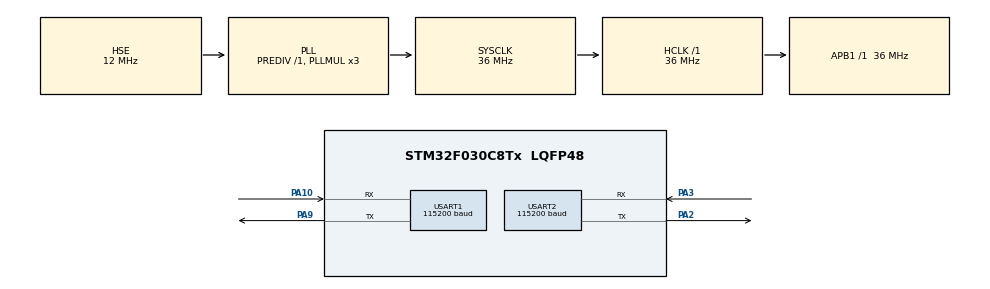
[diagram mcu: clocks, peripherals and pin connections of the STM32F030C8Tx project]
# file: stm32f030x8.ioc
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IWDG.Prescaler=IWDG_PRESCALER_256
Mcu.Family=STM32F0
Mcu.Name=STM32F030C8Tx
Mcu.Package=LQFP48
PA10.Mode=Asynchronous
PA10.Signal=USART1_RX
PA2.Mode=Asynchronous
PA2.Signal=USART2_TX
PA3.Mode=Asynchronous
PA3.Signal=USART2_RX
PA9.Mode=Asynchronous
PA9.Signal=USART1_TX
PF0-OSC_IN.Mode=HSE-External-Oscillator
PF0-OSC_IN.Signal=RCC_OSC_IN
PF1-OSC_OUT.Mode=HSE-External-Oscillator
PF1-OSC_OUT.Signal=RCC_OSC_OUT
ProjectManager.HeapSize=0x200
ProjectManager.StackSize=0x400
ProjectManager.TargetToolchain=Makefile
RCC.AHBFreq_Value=36000000
RCC.APB1Freq_Value=36000000
RCC.APB1TimFreq_Value=36000000
RCC.HCLKFreq_Value=36000000
RCC.HSE_VALUE=12000000
RCC.PLLMUL=RCC_PLL_MUL3
RCC.PLLSourceVirtual=RCC_PLLSOURCE_HSE
RCC.SYSCLKFreq_VALUE=36000000
RCC.SYSCLKSource=RCC_SYSCLKSOURCE_PLLCLK
USART1.BaudRate=115200
USART1.VirtualMode-Asynchronous=VM_ASYNC
USART2.BaudRate=115200
USART2.VirtualMode-Asynchronous=VM_ASYNC
VP_IWDG_VS_IWDG.Mode=IWDG_Activate
board=custom

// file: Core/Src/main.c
/* USER CODE BEGIN Header */
/**
  ******************************************************************************
  * @file           : main.c
  * @brief          : Main program body
  ******************************************************************************
  * @attention
  *
  * <h2><center>&copy; Copyright (c) 2022 STMicroelectronics.
  * All rights reserved.</center></h2>
  *
  * This software component is licensed by ST under BSD 3-Clause license,
  * the "License"; You may not use this file except in compliance with the
  * License. You may obtain a copy of the License at:
  *                        opensource.org/licenses/BSD-3-Clause
  *
  ******************************************************************************
  */
/* USER CODE END Header */
#include "main.h"

/* USER CODE BEGIN Includes */
#include "main_loop.h"

/* USER CODE END Includes */

IWDG_HandleTypeDef hiwdg;

UART_HandleTypeDef huart1;
UART_HandleTypeDef huart2;

void SystemClock_Config(void);
static void MX_GPIO_Init(void);
static void MX_IWDG_Init(void);
static void MX_USART1_UART_Init(void);
static void MX_USART2_UART_Init(void);

int main(void)
{

  /* MCU Configuration--------------------------------------------------------*/

  /* Reset of all peripherals, Initializes the Flash interface and the Systick. */
  HAL_Init();

  /* Configure the system clock */
  SystemClock_Config();

  /* Initialize all configured peripherals */
  MX_GPIO_Init();
  MX_IWDG_Init();
  MX_USART1_UART_Init();
  MX_USART2_UART_Init();
  /* USER CODE BEGIN 2 */

  /*for (int j=0; j<5; ++j)
  {
    volatile int i = 0;
    for(i=0;i<0x80000;++i) {;}
    HAL_GPIO_WritePin(GPIOB, GPIO_PIN_3, GPIO_PIN_RESET);
    for(i=0;i<0x80000;++i) {;}
    HAL_GPIO_WritePin(GPIOB, GPIO_PIN_3, GPIO_PIN_SET);
  }*/

  HAL_UART_Transmit(&huart1, (uint8_t*)"huart1\n", 7, 1000000);
  HAL_UART_Transmit(&huart2, (uint8_t*)"huart2\n", 7, 1000000);

  /* USER CODE END 2 */

  /* Infinite loop */
  /* USER CODE BEGIN WHILE */

  main_loop();

  while (1)
  {
    /* USER CODE END WHILE */

  }
}

void SystemClock_Config(void)
{
  RCC_OscInitTypeDef RCC_OscInitStruct = {0};
  RCC_ClkInitTypeDef RCC_ClkInitStruct = {0};
  RCC_PeriphCLKInitTypeDef PeriphClkInit = {0};

  /** Initializes the RCC Oscillators according to the specified parameters
  * in the RCC_OscInitTypeDef structure.
  */
  RCC_OscInitStruct.OscillatorType = RCC_OSCILLATORTYPE_LSI|RCC_OSCILLATORTYPE_HSE;
  RCC_OscInitStruct.HSEState = RCC_HSE_ON;
  RCC_OscInitStruct.LSIState = RCC_LSI_ON;
  RCC_OscInitStruct.PLL.PLLState = RCC_PLL_ON;
  RCC_OscInitStruct.PLL.PLLSource = RCC_PLLSOURCE_HSE;
  RCC_OscInitStruct.PLL.PLLMUL = RCC_PLL_MUL3;
  RCC_OscInitStruct.PLL.PREDIV = RCC_PREDIV_DIV1;
  if (HAL_RCC_OscConfig(&RCC_OscInitStruct) != HAL_OK)
  {
    Error_Handler();
  }

  /** Initializes the CPU, AHB and APB buses clocks
  */
  RCC_ClkInitStruct.ClockType = RCC_CLOCKTYPE_HCLK|RCC_CLOCKTYPE_SYSCLK
                              |RCC_CLOCKTYPE_PCLK1;
  RCC_ClkInitStruct.SYSCLKSource = RCC_SYSCLKSOURCE_PLLCLK;
  RCC_ClkInitStruct.AHBCLKDivider = RCC_SYSCLK_DIV1;
  RCC_ClkInitStruct.APB1CLKDivider = RCC_HCLK_DIV1;

  if (HAL_RCC_ClockConfig(&RCC_ClkInitStruct, FLASH_LATENCY_1) != HAL_OK)
  {
    Error_Handler();
  }
  PeriphClkInit.PeriphClockSelection = RCC_PERIPHCLK_USART1;
  PeriphClkInit.Usart1ClockSelection = RCC_USART1CLKSOURCE_PCLK1;
  if (HAL_RCCEx_PeriphCLKConfig(&PeriphClkInit) != HAL_OK)
  {
    Error_Handler();
  }
}

static void MX_IWDG_Init(void)
{

  hiwdg.Instance = IWDG;
  hiwdg.Init.Prescaler = IWDG_PRESCALER_256;
  hiwdg.Init.Window = 4095;
  hiwdg.Init.Reload = 4095;
  if (HAL_IWDG_Init(&hiwdg) != HAL_OK)
  {
    Error_Handler();
  }

}

static void MX_USART1_UART_Init(void)
{

  huart1.Instance = USART1;
  huart1.Init.BaudRate = 115200;
  huart1.Init.WordLength = UART_WORDLENGTH_8B;
  huart1.Init.StopBits = UART_STOPBITS_1;
  huart1.Init.Parity = UART_PARITY_NONE;
  huart1.Init.Mode = UART_MODE_TX_RX;
  huart1.Init.HwFlowCtl = UART_HWCONTROL_NONE;
  huart1.Init.OverSampling = UART_OVERSAMPLING_16;
  huart1.Init.OneBitSampling = UART_ONE_BIT_SAMPLE_DISABLE;
  huart1.AdvancedInit.AdvFeatureInit = UART_ADVFEATURE_NO_INIT;
  if (HAL_UART_Init(&huart1) != HAL_OK)
  {
    Error_Handler();
  }

}

static void MX_USART2_UART_Init(void)
{

  huart2.Instance = USART2;
  huart2.Init.BaudRate = 115200;
  huart2.Init.WordLength = UART_WORDLENGTH_8B;
  huart2.Init.StopBits = UART_STOPBITS_1;
  huart2.Init.Parity = UART_PARITY_NONE;
  huart2.Init.Mode = UART_MODE_TX_RX;
  huart2.Init.HwFlowCtl = UART_HWCONTROL_NONE;
  huart2.Init.OverSampling = UART_OVERSAMPLING_16;
  huart2.Init.OneBitSampling = UART_ONE_BIT_SAMPLE_DISABLE;
  huart2.AdvancedInit.AdvFeatureInit = UART_ADVFEATURE_NO_INIT;
  if (HAL_UART_Init(&huart2) != HAL_OK)
  {
    Error_Handler();
  }

}

static void MX_GPIO_Init(void)
{

  /* GPIO Ports Clock Enable */
  __HAL_RCC_GPIOF_CLK_ENABLE();
  __HAL_RCC_GPIOA_CLK_ENABLE();

}

void Error_Handler(void)
{
  /* USER CODE BEGIN Error_Handler_Debug */
  /* User can add his own implementation to report the HAL error return state */
  sysErrorHandler(SYS_ERROR_FROM_MX_MAIN);
  __disable_irq();
  while (1)
  {
  }
  /* USER CODE END Error_Handler_Debug */
}
